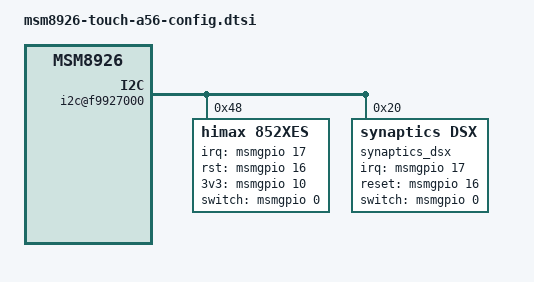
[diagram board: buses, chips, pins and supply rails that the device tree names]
&soc {
	touch_fw_update {
		compatible = "htc,touch_fwu";
	};
};

&soc {
	gen-vkeys {
		compatible = "qcom,gen-vkeys";
		label = "himax-touchscreen";
		vkey-num = <3>;

		cap-0 {
			keycode = <158>; /* KEY_BACK */
			/* Touch: 222:2027 */
			center-x = <148>;
			center-y = <1341>;
			range = "89:63"; /* Touch: 133.5:94 */
		};
		cap-1 {
			keycode = <102>; /* KEY_HOME */
			/* Touch: 540:2027 */
			center-x = <360>;
			center-y = <1341>;
			range = "83:63"; /* Touch: 125:94 */
		};
		cap-2 {
			keycode = <580>; /* KEY_APPSELECT */
			/* Touch: 853:2027 */
			center-x = <569>;
			center-y = <1341>;
			range = "83:63"; /* Touch: 125:94 */
		};
	};

	i2c@f9927000 { /* BLSP1 QUP5 */
	himax@48 {
		compatible		= "himax,852xes";
		reg			= <0x48>;
		interrupt-parent	= <&msmgpio>;
		interrupts		= <17 0x2>;
		support_htc_event	= <1>;
		himax,panel-coords	= <0 1080 0 1920>;
		himax,display-coords	= <0 720 0 1280>;
		himax,irq-gpio		= <&msmgpio 17 0x00>;
		himax,rst-gpio		= <&msmgpio 16 0x00>;
		himax,3v3-gpio		= <&msmgpio 10 0x00>;
		himax,switch-gpio 	= <&msmgpio 0 0x00>;
		report_type		= <1>;
		hall_block_touch_time	= <1000>;	/* msec */

		config2 {	//1st source
			cover_support;
			fw_ver		= <0x12>;
			sensor_id	= <0x22>;
			c1  = [ 5B 02 00 12 00 00 00 00 00 00 00];
			c2  = [ 5C 02 00 12 00 00 00 00 00 00 00];
			c3  = [ 5D 02 00 12 00 00 00 00 00 00 00];
			c4  = [ 5E 02 00 12 00 00 00 00 00 00 00];
			c5  = [ 5F 02 00 12 03 00 00 00 00 00 00];
			c6  = [ 60 02 00 12 03 00 00 00 00 00 00];
			c7  = [ 61 02 00 12 03 00 00 00 00 00 00];
			c8  = [ 62 02 00 12 03 00 00 00 00 00 00];
			c9  = [ 63 02 00 12 03 00 00 00 00 00 00];
			c10 = [ 64 02 00 12 03 00 00 00 00 00 00];
			c11 = [ 65 02 00 12 03 00 00 00 00 00 00];
			c12 = [ 66 02 00 12 03 00 00 00 00 00 00];
			c13 = [ 67 00 00 10 03 00 00 00 00 00 00];
			c14 = [ 68 00 00 20 03 00 00 00 00 00 00];
			c15 = [ 69 01 00 21 00 00 00 00 00 00 00];
			c16 = [ 6A 01 00 21 00 00 00 00 00 00 00];
			c17 = [ 6B 01 00 21 00 00 00 00 00 00 00];
			c18 = [ D5 29 00 00 00 00 00 00 00 00 00
				00 00 00 00 00 00];
			c19 = [ E1 06 01 01 01 01 03 0F 03 0F 03 0F 03 0F 08]; //
			c20 = [ BC 08 00 00 00]; //
			c21 = [ C5 0A 19 00 10 18 1E 0B 19 02 1F]; //Self Setting
			c22 = [ C6 14 10 1B]; //Mutual Setting
			c23 = [ BD 00 0B]; //SETCLK12
			c24 = [ B9 01 05]; //SET CVDD
			c25 = [ EC 10 DF 8D]; //SET PTBA
			c26 = [ B0 00]; //TX Floating
			c27 = [ DD 03]; //Set Cache
			c28 = [ 42 02]; //Reload Disable
			c29 = [ CE 00]; //HW Watch Dog
			c30 = [ CA 00]; //ESD Detector
			c31 = [ 3F 00]; //Dual Mode
			c32 = [ EB 03]; //SET AP
			c33 = [ BA 00]; //SET EQ
			c34 = [ BB 00]; //D0200 added.
			c35 = [ D3 06 01]; //TX Pumping Postivite
			c36 = [ 37 FF 08 FF 08]; //POWRSTB
			c37 = [ A4 94 62 94 86]; //Dual Mode
			c38 = [ ED 00 04 0A 0A 04 00 00 00]; //SET CLK
			c39 = [ CB 00 0F 0F FF FF 01 00 1F
				00 32 00 FF 00]; //GPIO_EN
			c40 = [ 40 0B 5A //Customer Info
				5F 00 F0 10 14 00 //Switch
				30 0A 0C 10 08 08 08 2F 1F 1F //Threshold
				30 28 40 40 40 24 A6 05 00 00 00 02 //Weighting
				74 0A F0 11 84 00 //Stability
				44 22 0F 0F 83 3C 00 00 //Palm
				11 00 41 42 //Enter
				1F 6F 00 18 00 00 //CCL
				08 01 3C 64 00 00 //Timer
				18 3F 3F 05 2F 00 00 00 //OSR Hopping
				04 06 24 06 06 00 00 00 //TX Hopping
				4C 40 0A 54 10 DF 8D 20 00 02
				03 10 00 00 00 00 //Idle
				00 02 80 00 00 00 00 0C //Water
				10 00 20 18 03 07 0B 00 //MKey
				C8 82 32 00 //Bank
				0F 1B A0 13 //Channel
				00 00 04 38 08 0A //Resolution
				01 61 03 9F 4F 02 10 00 40 01 3A 50 8A 10 //Fitting Curve 1
				03 5F 08 D8 57 64 00 00 90 02 BD 55 0D 00 //Fitting Curve 2
				00 01 00 00 00 00 00 00]; //OLM Gen1 Pattern
			c41 = [ 40 1B 1A 19 18 17 16 15 14 13 12 //Channel 1~17
				11 10 0F FF 0E 0D 0C
				0B 0A 09 08 07 06 05 04 03 02 //Channel 18~34
				01 00 FF 1C 1D 1E 1F
				FF FF FF FF 20 21 22 23 24 25 //Channel 35~51
				26 27 28 29 FF FF FF
				FF FF FF	//Channel 52~54
				07 10 27 0A 00 00 //Noise Matrix
				00 00 00 00 00 00 //Reserve
				00 00 00 00 00 00 //Reserve
				1A 7D 12 32 82 C2 05 00//Sensor Hub Gesture for HTC
				11 C4 45 C5 48 5C 03 55 00 00//High Sensitivity Mode
				00 00 00 00 00 00 //Reserve
				00 00]; //Checksum
		};

		config1 {	//2nd source
			cover_support;
			fw_ver		= <0x12>;
			sensor_id	= <0x21>;
			c1  = [ 5B 02 00 12 00 00 00 00 00 00 00];
			c2  = [ 5C 02 00 12 00 00 00 00 00 00 00];
			c3  = [ 5D 02 00 12 00 00 00 00 00 00 00];
			c4  = [ 5E 02 00 12 00 00 00 00 00 00 00];
			c5  = [ 5F 02 00 12 03 00 00 00 00 00 00];
			c6  = [ 60 02 00 12 03 00 00 00 00 00 00];
			c7  = [ 61 02 00 12 03 00 00 00 00 00 00];
			c8  = [ 62 02 00 12 03 00 00 00 00 00 00];
			c9  = [ 63 02 00 12 03 00 00 00 00 00 00];
			c10 = [ 64 02 00 12 03 00 00 00 00 00 00];
			c11 = [ 65 02 00 12 03 00 00 00 00 00 00];
			c12 = [ 66 02 00 12 03 00 00 00 00 00 00];
			c13 = [ 67 00 00 10 03 00 00 00 00 00 00];
			c14 = [ 68 00 00 20 03 00 00 00 00 00 00];
			c15 = [ 69 01 00 21 00 00 00 00 00 00 00];
			c16 = [ 6A 01 00 21 00 00 00 00 00 00 00];
			c17 = [ 6B 01 00 21 00 00 00 00 00 00 00];
			c18 = [ D5 29 00 00 00 00 00 00 00 00 00
				00 00 00 00 00 00];
			c19 = [ E1 06 01 01 01 01 03 0F 03 0F 03 0F 03 0F 08]; //
			c20 = [ BC 08 00 00 00]; //
			c21 = [ C5 0A 18 00 10 18 1E 0B 18 02 1F]; //Self Setting
			c22 = [ C6 13 10 1B]; //Mutual Setting
			c23 = [ BD 00 0B]; //SETCLK12
			c24 = [ B9 01 05]; //SET CVDD
			c25 = [ EC 10 DF 8D]; //SET PTBA
			c26 = [ B0 00]; //TX Floating
			c27 = [ DD 03]; //Set Cache
			c28 = [ 42 02]; //Reload Disable
			c29 = [ CE 00]; //HW Watch Dog
			c30 = [ CA 00]; //ESD Detector
			c31 = [ 3F 00]; //Dual Mode
			c32 = [ EB 03]; //SET AP
			c33 = [ BA 00]; //SET EQ
			c34 = [ BB 00]; //D0200 added.
			c35 = [ D3 06 01]; //TX Pumping Postivite
			c36 = [ 37 FF 08 FF 08]; //POWRSTB
			c37 = [ A4 94 62 94 86]; //Dual Mode
			c38 = [ ED 00 04 0A 0A 04 00 00 00]; //SET CLK
			c39 = [ CB 00 0F 0F FF FF 01 00 1F
				00 32 00 FF 00]; //GPIO_EN
			c40 = [ 40 25 5A //Customer Info
				5F 00 F0 10 14 00 //Switch
				30 0A 0C 10 08 08 08 2F 1F 1F //Threshold
				30 28 40 40 40 24 A6 05 00 00 00 02 //Weighting
				74 0A F0 11 84 00 //Stability
				44 22 0F 0F 83 3C 00 00 //Palm
				11 00 41 42 //Enter
				1F 6F 00 18 00 00 //CCL
				08 01 3C 64 00 00 //Timer
				18 3F 3F 05 2F 00 00 00 //OSR Hopping
				04 06 24 06 06 00 00 00 //TX Hopping
				4C 40 0A 54 10 DF 8D 20 00 02
				03 10 00 00 00 00 //Idle
				00 02 80 00 00 00 00 0C //Water
				10 00 20 18 03 07 0B 00 //MKey
				C8 82 32 00 //Bank
				0F 1B A0 13 //Channel
				00 00 04 38 08 0A //Resolution
				01 61 03 9F 4F 02 10 00 40 01 3A 50 8A 10 //Fitting Curve 1
				03 5F 08 D8 57 64 00 00 90 02 BD 55 0D 00 //Fitting Curve 2
				00 01 00 00 00 00 00 00]; //OLM Gen1 Pattern
			c41 = [ 40 1B 1A 19 18 17 16 15 14 13 12 //Channel 1~17
				11 10 0F FF 0E 0D 0C
				0B 0A 09 08 07 06 05 04 03 02 //Channel 18~34
				01 00 FF 1C 1D 1E 1F
				FF FF FF FF 20 21 22 23 24 25 //Channel 35~51
				26 27 28 29 FF FF FF
				FF FF FF	//Channel 52~54
				07 10 27 0A 00 00 //Noise Matrix
				00 00 00 00 00 00 //Reserve
				00 00 00 00 00 00 //Reserve
				1A 7D 12 32 82 C2 05 00//Sensor Hub Gesture for HTC
				11 C4 45 C5 48 5C 03 55 00 00//High Sensitivity Mode
				00 00 00 00 00 00 //Reserve
				00 00]; //Checksum
		};

		config0 {	//semi for XA
			fw_ver		= <0x12>;
			sensor_id	= <0x11>;
			c1  = [ 5B 02 00 02 00 00 00 00 00 00 00];
			c2  = [ 5C 02 00 12 00 00 00 00 00 00 00];
			c3  = [ 5D 02 00 02 01 00 00 00 00 00 00];
			c4  = [ 5E 02 00 12 00 00 00 00 00 00 00];
			c5  = [ 5F 02 00 32 01 00 00 00 00 00 00];
			c6  = [ 60 02 00 12 03 00 00 00 00 00 00];
			c7  = [ 61 02 00 32 01 00 00 00 00 00 00];
			c8  = [ 62 02 00 12 03 00 00 00 00 00 00];
			c9  = [ 63 02 00 32 01 00 00 00 00 00 00];
			c10 = [ 64 02 00 12 03 00 00 00 00 00 00];
			c11 = [ 65 02 00 32 01 00 00 00 00 00 00];
			c12 = [ 66 02 00 12 03 00 00 00 00 00 00];
			c13 = [ 67 00 00 30 00 00 00 00 00 00 00];
			c14 = [ 68 00 00 20 03 00 00 00 00 00 00];
			c15 = [ 69 01 00 01 02 00 00 00 00 00 00];
			c16 = [ 6A 01 00 21 00 00 00 00 00 00 00];
			c17 = [ 6B 01 00 01 02 00 00 00 00 00 00];
			c18 = [ D5 29 00 00 00 00 00 00 00 00 00
				00 00 00 00 00 00];
			c19 = [ E1 05 01 01 01 01 03 07 03 07 03 07 03 07 08]; //
			c20 = [ BC 00 00 00 00]; //
			c21 = [ C5 0A 1D 00 10 19 1E 0B 1D 02 1F]; //Self Setting
			c22 = [ C6 14 10 1B]; //Mutual Setting
			c23 = [ BD 00 0B]; //SETCLK12
			c24 = [ B9 01 05]; //SET CVDD
			c25 = [ EC 10 DF 8D]; //SET PTBA
			c26 = [ B0 00]; //TX Floating
			c27 = [ DD 03]; //Set Cache
			c28 = [ 42 02]; //Reload Disable
			c29 = [ CE 00]; //HW Watch Dog
			c30 = [ CA 00]; //ESD Detector
			c31 = [ 3F 00]; //Dual Mode
			c32 = [ EB 03]; //SET AP
			c33 = [ BA 00]; //SET EQ
			c34 = [ BB 00]; //D0200 added.
			c35 = [ D3 06 01]; //TX Pumping Postivite
			c36 = [ 37 FF 08 FF 08]; //POWRSTB
			c37 = [ A4 94 62 94 86]; //Dual Mode
			c38 = [ ED 00 04 0A 0A 04 00 00 00]; //SET CLK
			c39 = [ CB 00 0F 0F FF FF 01 00 1F
				00 32 00 FF 00]; //GPIO_EN
			c40 = [ 40 00 5A //Customer Info
				5F F1 00 10 64 00 //Switch
				1C 0F 0F 0F 09 09 09 0F 0F 0F //Threshold
				38 30 40 40 3A 00 00 00 00 00 00 00 //Weighting
				74 0A F0 83 86 00 //Stability
				44 22 0F 0F 83 3C 00 00 //Palm
				11 00 41 42 //Enter
				1F 6F 00 18 00 00 //CCL
				08 01 3C 64 00 00 //Timer
				28 37 37 05 10 55 00 00 //OSR Hopping
				04 06 24 05 05 00 00 00 //TX Hopping
				76 40 0A 54 10 DF 8D 20 00 02
				03 10 00 00 00 00 //Idle
				88 02 80 00 00 00 00 0C //Water
				10 00 20 18 03 07 0B 00 //MKey
				C8 82 32 00 //Bank
				0F 19 A0 13 //Channel
				00 00 04 38 07 80 //Resolution
				00 00 00 00 4D 25 00 00 00 00 00 50 00 0A //Fitting Curve 1
				00 00 00 00 4D 25 00 00 00 00 00 50 00 00 //Fitting Curve 2
				00 00 00 00 00 00 00 00]; //OLM Gen1 Pattern
			c41 = [ 40 FF 19 18 17 16 15 14 13 12 11 //Channel 1~17
				10 0F FF FF 01 00 03
				02 05 04 07 06 09 08 0B 0A 0D //Channel 18~34
				0C 0E FF 1B 1A 1D 1C
				FF FF FF FF 1F 1E 21 20 23 22 //Channel 35~51
				25 24 27 26 FF FF FF
				FF FF FF	//Channel 52~54
				07 10 27 0A 00 00 //Noise Matrix
				00 00 00 00 00 00 //Reserve
				00 00 00 00 00 00 //Reserve
				1A 7D 12 32 82 C2 05 00 //Sensor Hub Gesture for HTC
				11 C4 45 C5 48 5C 03 55 00 00 //High Sensitivity Mode
				00 00 00 00 00 00 //Reserve
				00 00]; //Checksum
		};
	};

	/delete-node/ synaptics@20;

	synaptics_dsx@20 {
		compatible = "synaptics,dsx";
		reg = <0x20>;
		interrupt-parent = <&msmgpio>;
		interrupts = <17 0>;
		synaptics,irq-gpio = <&msmgpio 17 0x00>;
		synaptics,irq-flags = <0x2008>;
		synaptics,reset-gpio = <&msmgpio 16 0x00>;
		synaptics,reset-on-state = <0>;
		synaptics,reset-active-ms = <1>;
		synaptics,reset-delay-ms = <20>;
		synaptics,switch-gpio = <&msmgpio 0 0x00>;
		synaptics,update-feature = <2>;
		//synaptics,support-glove = <1>;
		//synaptics,support-cover = <1>;
		//synaptics,hall-block-time = <1000>;
		synaptics,display-coords = <0 720 0 1280>;
		synaptics,tw-pin-mask = <0x3>;
		synaptics,y-flip; /* temporary */

		config_0 {	/* For semi */
			pr_number = <2093014>;
			sensor_id = <0x3>;
			config = [
				41 35 36 99 02 00 00 00
				00 00 00 00 00 00 00 00
				00 00 00 00 00 00 00 00
				00 00 00 00 00 00 00 00
				00 4F 03 0F 05 51 0E 38
				04 80 07 14 3E 0A 3F 00
				00 31 20 0F 19 1E 05 53
				10 E5 03 2D 31 FF 41 FD
				C2 CF 3D CD 7F 13 03 68
				01 00 0A 16 64 0F 0A 50
				00 01 01 07 04 04 32 28
				08 C8 26 26 80 80 00 00
				FF C0 53 5B 80 39 38 00
				40 28 32 50 00 00 00 00
				38 04 80 07 3C 32 00 00
				00 00 38 04 80 07 1E 05
				1E 04 0A 04 0A 00 0A 04
				04 00 0A 78 02 00 7D 00
				02 00 C8 00 00 00 96 00
				00 00 00 01 05 0A 00 00
				00 78 00 96 00 32 00 00
				00 00 00 00 00 00 00 0D
				00 00 14 03 0C 0F 0A 00
				4B 00 00 FF FF FF FF FF
				FF FF FF FF FF FF FF FF
				FF FF FF FF FF FF FF FF
				FF FF FF FF FF FF FF FF
				FF FF FF FF 00 01 00 00
				32 00 14 00 14 00 64 00
				64 00 10 00 10 00 7D 00
				7D 00 40 66 58 1B 28 00
				FF FF FF FF FF FF FF FF
				FF FF FF FF FF FF FF FF
				01 00 00 00 00 00 00 00
				00 00 00 00 00 00 00 00
				00 00 00 00 00 00 00 FF
				00 FF 14 55 09 0E 3C 0A
				0F 64 64 00 00 00 00 00
				00 00 00 00 00 00 00 00
				00 00 00 00 00 FF FF FF
				FF FF FF FF FF FF FF FF
				FF FF FF FF FF FF FF FF
				FF FF FF FF FF FF FF FF
				FF FF FF FF FF FF FF FF
				FF FF FF FF FF FF FF FF
				FF FF FF FF FF FF FF FF
				FF FF FF FF FF FF FF FF
				FF FF FF FF FF 00 00 D2
				00 80 04 1B 00 00 FF C8
				00 FF FF 80 C8 E8 03 00
				C0 80 04 10 0A 18 00 79
				08 0A 00 01 2C 01 06 00
				03 03 05 05 02 FA 00 01
				04 03 2D 00 12 00 00 00
				03 00 01 26 03 2D 00 11
				00 02 00 03 00 01 28 03
				2D 00 11 00 04 00 03 00
				01 29 03 2D 00 10 00 06
				00 07 00 02 25 83 2D 00
				10 00 08 00 07 00 02 26
				83 2D 00 0F 00 0A 00 07
				00 02 27 83 2D 00 0F 00
				0C 00 04 00 01 23 83 2D
				00 0F 00 0E 00 04 00 01
				24 07 07 07 07 07 07 07
				07 07 07 07 07 07 07 07
				00 00 00 00 00 00 00 00
				00 00 00 00 00 00 00 00
				00 00 00 2C 00 06 00 A6
				00 0A 14 00 01 1B 02 06
				AD 74 50 00 50 00 A4 4C
				1E 03 0C 0C 14 28 04 00
				00 00 00 00 00 00 00 00
				00 11 00 00 07 01 07 07
				1D 1D 00 00 07 07 01 07
				07 1D 1D 00 00 07 04 04
				52 00 07 03 00 2D 22 00
				05 0B 00 23 02 00 00 04
				0D BB BB 00 0D CC CC 55
				01 32 0C 99 99 55 0C BB
				BB AA 00 00 00 FF FF FF
				FF FF FF FF FF 51 51 51
				51 CD 0D 04 83 10 10 10
				10 61 24 64 01 19 1C 1F
				1E 16 17 18 1A 14 15 11
				13 04 12 05 FF FF FF FF
				FF FF FF FF FF FF FF FF
				FF FF FF FF FF FF FF 2E
				30 28 2F 2D 27 2A 29 2B
				2C 23 26 25 24 39 35 3C
				3A 3B 3E 3F 31 36 38 3D
				FF FF FF FF FF FF FF FF
				FF 00 10 00 10 00 10 00
				10 80 80 80 80 80 80 80
				80 80 80 80 80 80 80 80
				80 80 80 80 80 80 80 80
				80 80 80 80 80 80 80 80
				80 80 80 80 80 80 80 80
				80 80 80 80 80 80 80 80
				80 80 80 80 80 80 80 80
				80 80 80 80 80 80 80 80
				80 80 80 80 80 00 10 00
				10 00 10 00 10 00 00 FF
				FF FF FF FF FF FF FF 00
				00 0F 00 44 44
			];
		};
	};
	};
};
